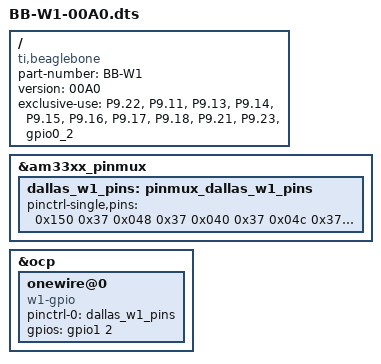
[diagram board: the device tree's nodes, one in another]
/dts-v1/;
/plugin/;

/ {
	compatible = "ti,beaglebone", "ti,beaglebone-black";

	part-number = "BB-W1";
	version = "00A0";

	/* state the resources this cape uses */
	exclusive-use =
		/* the pin header uses */
		"P9.22","P9.11","P9.13","P9.14","P9.15","P9.16","P9.17","P9.18","P9.21","P9.23",
		/* the hardware IP uses */
		"gpio0_2";

	fragment@0 {
               target = <&am33xx_pinmux>;
               __overlay__ {
					dallas_w1_pins: pinmux_dallas_w1_pins {
						pinctrl-single,pins = < 
						    0x150 0x37 /* P9_22 INPUT | MODE */
							
							0x048 0x37 /* P9_14 INPUT | MODE */
							0x040 0x37 /* P9_15 INPUT | MODE */
							0x04c 0x37 /* P9_16 INPUT | MODE */
							0x15c 0x37 /* P9_17 INPUT | MODE */
							0x158 0x37 /* P9_18 INPUT | MODE */
							0x154 0x37 /* P9_21 INPUT | MODE */
							0x044 0x37 /* P9_23 INPUT | MODE */ 	
							0x070 0x26  /* P9_11 = GPIO0_30 = GPMC_WAIT0 , MODE6 */
                            0x074 0x06  /* P9_13 = GPIO0_31 = GPMC_WPN, MODE6 */					
							>;
					};
               };
	};

	fragment@1 {
               target = <&ocp>;
               __overlay__ {
		       onewire@0 {
			       compatible      = "w1-gpio";
			       pinctrl-names   = "default";
			       pinctrl-0       = <&dallas_w1_pins>;
			       status          = "okay";

			       gpios = <&gpio1 2 0>;
		       };
         };
	};
};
